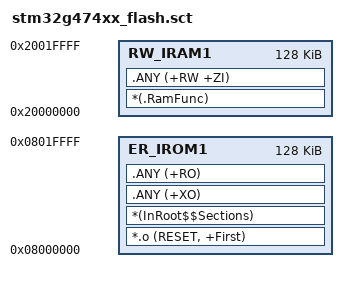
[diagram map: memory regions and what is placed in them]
LR_IROM1 0x8000000 0x00020000  {  ; load_region size_region (last 8KB reserved for param A/B)
  ER_IROM1 0x8000000 0x00020000  {  ; load address = excetion address
   *.o (RESET, +First)
   *(InRoot$$Sections)
   .ANY (+XO)
   .ANY (+RO)
  }
  RW_IRAM1 0x20000000 0x00020000  {  ; load address = excetion address
   *(.RamFunc)
   .ANY (+RW +ZI)
  }
;***region***;
;***endregion***;
}


/*-Start of  regions- Auto-generated By STM32CubeMX-*/
